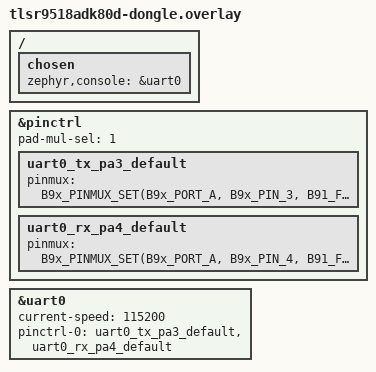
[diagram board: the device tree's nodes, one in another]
/*
 * Copyright (c) 2021-2024 Telink Semiconductor
 *
 * SPDX-License-Identifier: Apache-2.0
 */

#include <zephyr/dt-bindings/pinctrl/b91-pinctrl.h>

/ {
	chosen {
		zephyr,console = &uart0;
	};
};

&pinctrl {
	pad-mul-sel = <1>;

	uart0_tx_pa3_default: uart0_tx_pa3_default {
		pinmux = <B9x_PINMUX_SET(B9x_PORT_A, B9x_PIN_3, B91_FUNC_B)>;
	};
	uart0_rx_pa4_default: uart0_rx_pa4_default {
		pinmux = <B9x_PINMUX_SET(B9x_PORT_A, B9x_PIN_4, B91_FUNC_B)>;
	};
};

&uart0 {
	status = "okay";
	current-speed = <115200>;
	pinctrl-0 = <&uart0_tx_pa3_default &uart0_rx_pa4_default>;
	pinctrl-names = "default";
};
